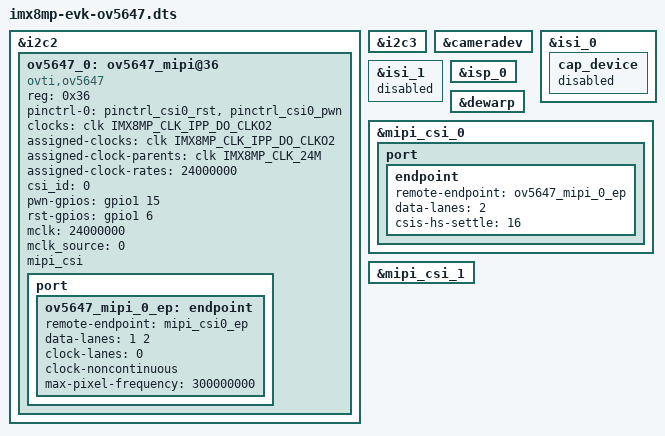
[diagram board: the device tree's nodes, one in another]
/*
 * Copyright 2022-2024 NXP
 * SPDX-License-Identifier: (GPL-2.0-only OR MIT)
 */

/dts-v1/;

#include "imx8mp-evk.dts"

&i2c2 {
	/delete-node/ov5640_mipi@3c;

	ov5647_0: ov5647_mipi@36 {
		compatible = "ovti,ov5647";
		reg = <0x36>;
		pinctrl-names = "default";
		pinctrl-0 = <&pinctrl_csi0_rst> ,<&pinctrl_csi0_pwn>; 
		clocks = <&clk IMX8MP_CLK_IPP_DO_CLKO2>;
		clock-names = "xclk";
		assigned-clocks = <&clk IMX8MP_CLK_IPP_DO_CLKO2>;
		assigned-clock-parents = <&clk IMX8MP_CLK_24M>;
		assigned-clock-rates = <24000000>;
		csi_id = <0>;
		pwn-gpios = <&gpio1 15 GPIO_ACTIVE_HIGH>;
		rst-gpios = <&gpio1 6 GPIO_ACTIVE_HIGH>;		
		mclk = <24000000>;
		mclk_source = <0>;

		mipi_csi;
		status = "okay";

		port {
			ov5647_mipi_0_ep: endpoint {
				remote-endpoint = <&mipi_csi0_ep>;				
				data-lanes = <1 2>;
				clock-lanes = <0>;
				clock-noncontinuous;
				max-pixel-frequency = /bits/ 64 <300000000>;
	
			};
		};
	};
};

&i2c3 {
	/delete-node/ov5640_mipi@3c;

};

&cameradev {
	status = "okay";
};

&isi_0 {
	cap_device {
		status = "disabled";
	};
};

&isi_1 {
	status = "disabled";
};

&isp_0 {
	status = "okay";
};

&dewarp {
	status = "okay";
};

&mipi_csi_0 {
	status = "okay";

	port {
		endpoint {
			remote-endpoint = <&ov5647_mipi_0_ep>;
			data-lanes = <2>;
			csis-hs-settle = <16>;
		};
	};
};

&mipi_csi_1 {
	/delete-property/ #address-cells;
	/delete-property/ #size-cells;
	/delete-node/port@1;
};










